# pse84 register map
Vendor: Infineon Technologies; Series: PSE84; File version: 1.0
CPU: CM33 r0p1, little endian, MPU, FPU, VTOR, 3 interrupt priority bits
Registers are 32-bit, read-write, reset 0x0 unless marked. A register's access mark holds for its fields unless they carry their own. Offsets are from the block's base; [hi:lo] are bit positions; lines under a group give offsets from that group; {n}, {i} and the like mark numbered series.

## LPPASS_MMIO — LPPASS top-level MMIO
Base 0x42EF0000
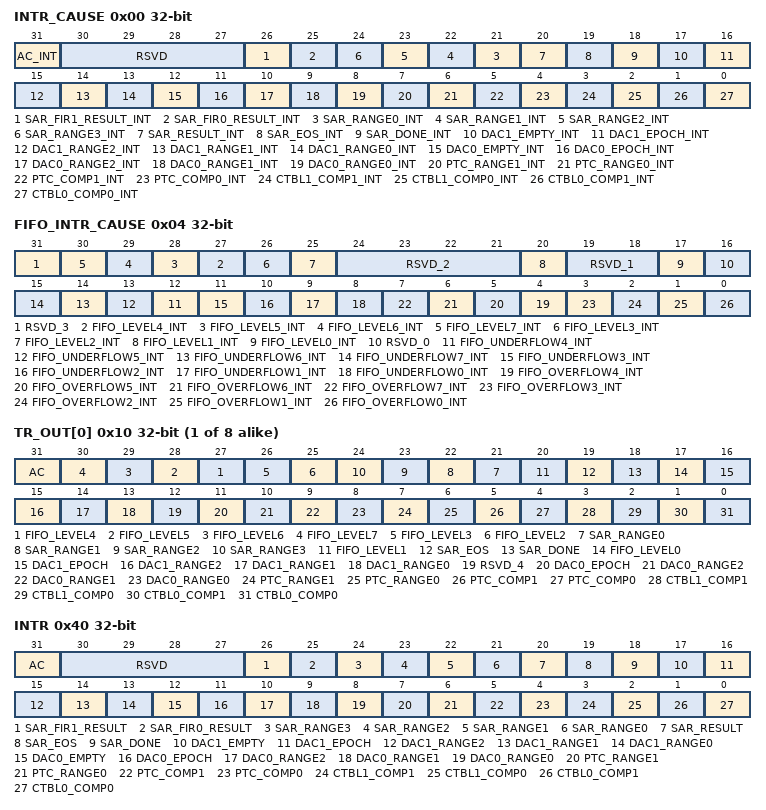
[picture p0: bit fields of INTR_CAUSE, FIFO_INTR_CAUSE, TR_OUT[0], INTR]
0x00 INTR_CAUSE ro — Interrupt cause register
  [31] AC_INT — Autonomus Controller Interrupt Pending This interrupt is set by the Autonomus Controller whenever executing a state with ACTRLR.TIMER_TABLE_STRUCT.TT_CFG1.INTR_SET=1.
  [30:27] RSVD
  [26] SAR_FIR1_RESULT_INT — FIR1 Result Interrupt Pending This interrupt is set by SAR FIR1 whenever it generates a new result. The corresponding bit in SAR_STA_CFG.FIR_RESULT_MASK must be set in order for the FIR to generate the interrupt source.
  [25] SAR_FIR0_RESULT_INT — FIR0 Result Interrupt Pending This interrupt is set by SAR FIR0 whenever it generates a new result. The corresponding bit in SAR_STA_CFG.FIR_RESULT_MASK must be set in order for the FIR to generate the interrupt source.
  [n+21] SAR_RANGE{n}_INT (n=0..3) — SAR Range {n} detection Interrupt Pending This interrupt is set by the SAR if the RANGE{n} condition is met for a given channel with range {n} status enabled (i.e. SAR_STA_CFG.GPIO(MUX)_CHAN_CFG.STATUS_SEL=STATUS_STRUCT_{n}). Firmware must read SAR_STA_CFG.RANGE_STATUS to determine which channel generated the interrupt.
  [20] SAR_RESULT_INT — SAR Result Interrupt Pending This interrupt is set by the SAR when a channel writes data into its associated result register. Firmware must read SAR_STA_CFG.CHAN_RESULT_UPDATED to determine which channel generated the interrupt. The corresponding bit in SAR_STA_CFG.CHAN_RESULT_MASK must be set in order for the SAR to generate the interrupt source.
  [19] SAR_EOS_INT — SAR Sequencer EOS Interrupt Pending This interrupt is set by the SAR when finishing the state in the SAR sequencer table (HS or LP) where SAR.SEQ_HS(LP)_DATA.NEXT_STATE is set to GO_TO_ENTRY_ADDRESS or STOP. This interrupt does NOT indicate that the SAR data has been written to the FIFO (the FIFO level interrupts should be used instead).
  [18] SAR_DONE_INT — SAR Sequencer Done Interrupt Pending This interrupt is set by the SAR when finishing a state in the SAR sequencer table (HS or LP) where SAR.SEQ_HS(LP)_DATA.NEXT_STATE is set to STOP. The interrupt is not generated if the SAR is configured for CONTINUOUS operation (i.e. SAR.SEQ_HS(LP)_DATA.NEXT_STATE is set to GO_TO_ENTRY_ADDRESS). This interrupt does NOT indicate that the SAR data has been written to the FIFO (the FIFO level interrupts should be used instead).
  [17] DAC1_EMPTY_INT — DAC1 Empty Interrupt Pending It is set by DAC1 when it empties the contents of its FW_DAC_VAL register. This interrupt is only generated if DAC1 is configured for FW operation (ACTRLR.TIMER_TABLE_STRUCT.TT_CFG3.DAC1_CHANNEL=FW_CHANNEL.
  [16] DAC1_EPOCH_INT — DAC1 End of Waveform Interrupt Pending It is set by DAC1 when finishing a waveform. This condition is only used if the DAC0 channel (pointed to by the AC when triggered) is configured for LUT mode.
  [15] DAC1_RANGE2_INT — DAC1 Range 2 Interrupt Pending It is set by the DAC1 if the RANGE2 condition is met for a given channel with range 2 status enabled (i.e. DAC1_STA_CFG.CHAN_CFG.STATUS_SEL=STATUS_2). The interrupt is disabled when DAC1 is configured for FW mode.
  [14] DAC1_RANGE1_INT — DAC1 Range 1 Interrupt Pending It is set by the DAC1 if the RANGE1 condition is met for a given channel with range 1 status enabled (i.e. DAC1_STA_CFG.CHAN_CFG.STATUS_SEL=STATUS_1). The interrupt is disabled when DAC1 is configured for FW mode.
  [13] DAC1_RANGE0_INT — DAC1 Range 0 Interrupt Pending It is set by the DAC1 if the RANGE0 condition is met for a given channel with range 0 status enabled (i.e. DAC1_STA_CFG.CHAN_CFG.STATUS_SEL=STATUS_0). The interrupt is disabled when DAC1 is configured for FW mode.
  [12] DAC0_EMPTY_INT — DAC0 Empty Interrupt Pending It is set by DAC0 when it empties the contents of its FW_DAC_VAL register. This interrupt is only generated if DAC0 is configured for FW operation (ACTRLR.TIMER_TABLE_STRUCT.TT_CFG3.DAC0_CHANNEL=FW_CHANNEL.
  [11] DAC0_EPOCH_INT — DAC0 End of Waveform Interrupt Pending It is set by DAC0 when finishing a waveform. This condition is only used if the DAC0 channel (pointed to by the AC when triggered) is configured for LUT mode.
  [10] DAC0_RANGE2_INT — DAC0 Range 2 Interrupt Pending It is set by the DAC0 if the RANGE2 condition is met for a given channel with range 2 status enabled (i.e. DAC0_STA_CFG.CHAN_CFG.STATUS_SEL=STATUS_2). The interrupt is disabled when DAC0 is configured for FW mode.
  [9] DAC0_RANGE1_INT — DAC0 Range 1 Interrupt Pending It is set by the DAC0 if the RANGE1 condition is met for a given channel with range 1 status enabled (i.e. DAC0_STA_CFG.CHAN_CFG.STATUS_SEL=STATUS_1). The interrupt is disabled when DAC0 is configured for FW mode.
  [8] DAC0_RANGE0_INT — DAC0 Range 0 Interrupt Pending It is set by the DAC0 if the RANGE0 condition is met for a given channel with range 0 status enabled (i.e. DAC0_STA_CFG.CHAN_CFG.STATUS_SEL=STATUS_0). The interrupt is disabled when DAC0 is configured for FW mode.
  [7] PTC_RANGE1_INT — PTC Post Processor 1 Range Interrupt Pending It is set by the PTC Post Processor if the RANGE0 condition is met (i.e. PTC_PP_STRUCT1.*).
  [6] PTC_RANGE0_INT — PTC Post Processor 0 Range Interrupt Pending It is set by the PTC Post Processor if the RANGE0 condition is met (i.e. PTC_PP_STRUCT0.*).
  [5] PTC_COMP1_INT — PTC Comparator 1 Interrupt Pending It is set by the PTC Comparator 1 if the condition is met (i.e. PTC_STA_CFG.CFG.COMP1_OUT field).
  [4] PTC_COMP0_INT — PTC Comparator 0 Interrupt Pending It is set by the PTC Comparator 0 if the condition is met (i.e. PTC_STA_CFG.CFG.COMP0_OUT field).
  [3] CTBL1_COMP1_INT — CTBL1 Comparator 1 Interrupt Pending It is set by the CTBL1 Opamp1 Comparator if the condition is met (i.e. CTBL_STA_CFG.CFG.COMP1_OUT field).
  [2] CTBL1_COMP0_INT — CTBL1 Comparator 0 Interrupt Pending It is set by the CTBL1 Opamp0 Comparator if the condition is met (i.e. CTBL_STA_CFG.CFG.COMP0_OUT field).
  [1] CTBL0_COMP1_INT — CTBL0 Comparator 1 Interrupt Pending It is set by the CTBL0 Opamp1 Comparator if the condition is met (i.e. CTBL_STA_CFG.CFG.COMP1_OUT field).
  [0] CTBL0_COMP0_INT — CTBL0 Comparator 0 Interrupt Pending It is set by the CTBL0 Opamp0 Comparator if the condition is met (i.e. CTBL_STA_CFG.CFG.COMP0_OUT field).
0x04 FIFO_INTR_CAUSE ro — FIFO Interrupt cause register
  [31] RSVD_3
  [n+23] FIFO_LEVEL{n}_INT (n=4..7) — FIFO Level {n} Interrupt Pending This level sensitive interrupt is set by the FIFO whenever FIFO {n} meets the FIFO_STA_CFG.LEVEL{n}.LEVEL condition. This interrupt is only generated if the FIFO is configured for multiple FIFOs (i.e. FIFO_STA_CFG.CFG.SEL=3)
  [26] FIFO_LEVEL3_INT — FIFO Level 3 Interrupt Pending This level sensitive interrupt is set by the FIFO whenever FIFO 3 meets the FIFO_STA_CFG.LEVEL3.LEVEL condition. This interrupt is only generated if the FIFO is configured for multiple FIFOs (i.e. FIFO_STA_CFG.CFG.SEL=2, or 3)
  [25] FIFO_LEVEL2_INT — FIFO Level 2 Interrupt Pending This level sensitive interrupt is set by the FIFO whenever FIFO 2 meets the FIFO_STA_CFG.LEVEL2.LEVEL condition. This interrupt is only generated if the FIFO is configured for multiple FIFOs (i.e. FIFO_STA_CFG.CFG.SEL=2, or 3)
  [24:21] RSVD_2
  [20] FIFO_LEVEL1_INT — FIFO Level 1 Interrupt Pending This level sensitive interrupt is set by the FIFO whenever FIFO 1 meets the FIFO_STA_CFG.LEVEL1.LEVEL condition. This interrupt is only generated if the FIFO is configured for multiple FIFOs (i.e. FIFO_STA_CFG.CFG.SEL=1,2, or 3)
  [19:18] RSVD_1
  [17] FIFO_LEVEL0_INT — FIFO Level 0 Interrupt Pending This level sensitive interrupt is set by the FIFO whenever FIFO 0 meets the FIFO_STA_CFG.LEVEL0.LEVEL condition.
  [16] RSVD_0
  [n+8] FIFO_UNDERFLOW{n}_INT (n=4..7) — FIFO Underflow {n} Interrupt Pending This interrupt is set by the FIFO whenever FIFO {n} underflows (i.e. a read from FIFO {n} fails because FIFO {n} is empty). This interrupt is only generated if the FIFO is configured for multiple FIFOs (i.e. FIFO_STA_CFG.CFG.SEL=3)
  [11] FIFO_UNDERFLOW3_INT — FIFO Overflow 3 Interrupt Pending This interrupt is set by the FIFO whenever FIFO 3 underflows (i.e. a read from FIFO 3 fails because FIFO 3 is empty). This interrupt is only generated if the FIFO is configured for multiple FIFOs (i.e. FIFO_STA_CFG.CFG.SEL=2, or 3)
  [10] FIFO_UNDERFLOW2_INT — FIFO Overflow 2 Interrupt Pending This interrupt is set by the FIFO whenever FIFO 2 underflows (i.e. a read from FIFO 2 fails because FIFO 2 is empty). This interrupt is only generated if the FIFO is configured for multiple FIFOs (i.e. FIFO_STA_CFG.CFG.SEL=2, or 3)
  [9] FIFO_UNDERFLOW1_INT — FIFO Overflow 1 Interrupt Pending This interrupt is set by the FIFO whenever FIFO 1 underflows (i.e. a read from FIFO 1 fails because FIFO 1 is empty). This interrupt is only generated if the FIFO is configured for multiple FIFOs (i.e. FIFO_STA_CFG.CFG.SEL=1,2, or 3)
  [8] FIFO_UNDERFLOW0_INT — FIFO Underflow 0 Interrupt Pending This interrupt is set by the FIFO whenever FIFO 0 underflows (i.e. a read from FIFO 0 fails because FIFO 0 is empty.
  [n] FIFO_OVERFLOW{n}_INT (n=4..7) — FIFO Overflow {n} Interrupt Pending This interrupt is set by the FIFO whenever FIFO {n} overflows (i.e. a write to FIFO {n} fails because FIFO {n} is full). This interrupt is only generated if the FIFO is configured for multiple FIFOs (i.e. FIFO_STA_CFG.CFG.SEL=3)
  [3] FIFO_OVERFLOW3_INT — FIFO Overflow 3 Interrupt Pending This interrupt is set by the FIFO whenever FIFO 3 overflows (i.e. a write to FIFO 3 fails because FIFO 3 is full). This interrupt is only generated if the FIFO is configured for multiple FIFOs (i.e. FIFO_STA_CFG.CFG.SEL=2, or 3)
  [2] FIFO_OVERFLOW2_INT — FIFO Overflow 2 Interrupt Pending This interrupt is set by the FIFO whenever FIFO 2 overflows (i.e. a write to FIFO 2 fails because FIFO 2 is full). This interrupt is only generated if the FIFO is configured for multiple FIFOs (i.e. FIFO_STA_CFG.CFG.SEL=2, or 3)
  [1] FIFO_OVERFLOW1_INT — FIFO Overflow 1 Interrupt Pending This interrupt is set by the FIFO whenever FIFO 1 overflows (i.e. a write to FIFO 1 fails because FIFO 1 is full). This interrupt is only generated if the FIFO is configured for multiple FIFOs (i.e. FIFO_STA_CFG.CFG.SEL=1,2, or 3)
  [0] FIFO_OVERFLOW0_INT — FIFO Overflow 0 Interrupt Pending This interrupt is set by the FIFO whenever FIFO 0 overflows (i.e. a write to FIFO 0 fails because FIFO 0 is full).
{0x10+4i} TR_OUT[{i}] (i=0..7) — Trigger out select register
  [31] AC — Autonomus Controller Trigger This trigger is set by the Autonomus Controller whenever executing a state with ACTRLR.TIMER_TABLE_STRUCT.TT_CFG1.INTR_SET=1.
  [n+23] FIFO_LEVEL{n} (n=4..7) — FIFO Level {n} Trigger This level sensitive trigger is set by the FIFO whenever FIFO {n} meets the FIFO_STA_CFG.LEVEL{n}.LEVEL condition. This trigger is only generated if the FIFO is configured for multiple FIFOs (i.e. FIFO_STA_CFG.CFG.SEL=3)
  [26] FIFO_LEVEL3 — FIFO Level 3 Trigger This level sensitive trigger is set by the FIFO whenever FIFO 3 meets the FIFO_STA_CFG.LEVEL3.LEVEL condition. This trigger is only generated if the FIFO is configured for multiple FIFOs (i.e. FIFO_STA_CFG.CFG.SEL=2, or 3)
  [25] FIFO_LEVEL2 — FIFO Level 2 Trigger This level sensitive trigger is set by the FIFO whenever FIFO 2 meets the FIFO_STA_CFG.LEVEL2.LEVEL condition. This trigger is only generated if the FIFO is configured for multiple FIFOs (i.e. FIFO_STA_CFG.CFG.SEL=2, or 3)
  [n+21] SAR_RANGE{n} (n=0..3) — SAR Range {n} Trigger This trigger is set by the SAR if the RANGE{n} condition is met for a given channel with range {n} status enabled (i.e. SAR_STA_CFG.GPIO(MUX)_CHAN_CFG.STATUS_SEL=STATUS_STRUCT_{n}). Firmware must read SAR_STA_CFG.RANGE_STATUS to determine which channel generated the trigger.
  [20] FIFO_LEVEL1 — FIFO Level 1 Trigger This level sensitive trigger is generated by the FIFO whenever FIFO 1 meets the FIFO_STA_CFG.LEVEL1.LEVEL condition. This trigger is only generated if the FIFO is configured for multiple FIFOs (i.e. FIFO_STA_CFG.CFG.SEL=1,2, or 3)
  [19] SAR_EOS — SAR Sequencer EOS Trigger This itrigger is set by the SAR when finishing the state in the SAR sequencer table (HS or LP) where SAR.SEQ_HS(LP)_DATA.NEXT_STATE is set to GO_TO_ENTRY_ADDRESS or STOP. This trigger does NOT indicate that the SAR data has been written to the FIFO (the FIFO level triggers should be used instead).
  [18] SAR_DONE — SAR Sequencer Done Trigger This trigger is set by the SAR when finishing a state in the SAR sequencer table (HS or LP) where SAR.SEQ_HS(LP)_DATA.NEXT_STATE is set to STOP. The interrupt is not generated if the SAR is configured for CONTINUOUS operation (i.e. SAR.SEQ_HS(LP)_DATA.NEXT_STATE is set to GO_TO_ENTRY_ADDRESS). This trigger does NOT indicate that the SAR data has been written to the FIFO (the FIFO level triggers should be used instead).
  [17] FIFO_LEVEL0 — FIFO Level 0 Trigger This is a level sensitive trigger that is generated by the FIFO whenever FIFO 0 meets the FIFO_STA_CFG.LEVEL0.LEVEL condition.
  [16] DAC1_EPOCH — DAC1 End of Waveform Trigger It is generated by DAC1 when finishing a waveform. This condition is only used if the DAC1 channel (pointed to by the AC when triggered) is configured for LUT mode.
  [15] DAC1_RANGE2 — DAC1 Range 2 Trigger It is generated by the DAC1 if the RANGE2 condition is met for a given channel with range 2 status enabled (i.e. DAC1_STA_CFG.CHAN_CFG.STATUS_SEL=STATUS_2). The interrupt is disabled when DAC1 is configured for FW mode.
  [14] DAC1_RANGE1 — DAC1 Range 1 Trigger It is generated by the DAC1 if the RANGE1 condition is met for a given channel with range 1 status enabled (i.e. DAC1_STA_CFG.CHAN_CFG.STATUS_SEL=STATUS_1). The interrupt is disabled when DAC1 is configured for FW mode.
  [13] DAC1_RANGE0 — DAC1 Range 0 Trigger It is generated by the DAC1 if the RANGE0 condition is met for a given channel with range 0 status enabled (i.e. DAC1_STA_CFG.CHAN_CFG.STATUS_SEL=STATUS_0). The interrupt is disabled when DAC1 is configured for FW mode.
  [12] RSVD_4
  [11] DAC0_EPOCH — DAC0 End of Waveform Trigger It is generated by DAC0 when finishing a waveform. This condition is only used if the DAC0 channel (pointed to by the AC when triggered) is configured for LUT mode.
  [10] DAC0_RANGE2 — DAC0 Range 2 Trigger It is generated by the DAC0 if the RANGE2 condition is met for a given channel with range 2 status enabled (i.e. DAC0_STA_CFG.CHAN_CFG.STATUS_SEL=STATUS_2). The interrupt is disabled when DAC0 is configured for FW mode.
  [9] DAC0_RANGE1 — DAC0 Range 1 Trigger It is generated by the DAC0 if the RANGE1 condition is met for a given channel with range 1 status enabled (i.e. DAC0_STA_CFG.CHAN_CFG.STATUS_SEL=STATUS_1). The interrupt is disabled when DAC0 is configured for FW mode.
  [8] DAC0_RANGE0 — DAC0 Range 0 Trigger It is generated by the DAC0 if the RANGE0 condition is met for a given channel with range 0 status enabled (i.e. DAC0_STA_CFG.CHAN_CFG.STATUS_SEL=STATUS_0). The interrupt is disabled when DAC0 is configured for FW mode.
  [7] PTC_RANGE1 — PTC Post Processor 1 Range Trigger It is generated by the PTC Post Processor if the RANGE0 condition is met (i.e. PTC_PP_STRUCT1.*).
  [6] PTC_RANGE0 — PTC Post Processor 0 Range Trigger It is generated by the PTC Post Processor if the RANGE0 condition is met (i.e. PTC_PP_STRUCT0.*).
  [5] PTC_COMP1 — PTC Comparator 1 Interrupt Pending It is set by the PTC Comparator 1 if the condition is met (i.e. PTC_STA_CFG.CFG.COMP1_OUT field).
  [4] PTC_COMP0 — PTC Comparator 0 Trigger It is set by the PTC Comparator 0 if the condition is met (i.e. PTC_STA_CFG.CFG.COMP0_OUT field).
  [3] CTBL1_COMP1 — CTBL1 Comparator 1 Trigger It is generated by the CTBL1 Opamp1 Comparator if the condition is met (i.e. CTBL_STA_CFG.CFG.COMP1_OUT field).
  [2] CTBL1_COMP0 — CTBL1 Comparator 0 Trigger It is generated by the CTBL1 Opamp0 Comparator if the condition is met (i.e. CTBL_STA_CFG.CFG.COMP0_OUT field).
  [1] CTBL0_COMP1 — CTBL0 Comparator 1 Trigger It is generated by the CTBL0 Opamp1 Comparator if the condition is met (i.e. CTBL_STA_CFG.CFG.COMP1_OUT field).
  [0] CTBL0_COMP0 — CTBL0 Comparator 0 Trigger It is generated by the CTBL0 Opamp0 Comparator if the condition is met (i.e. CTBL_STA_CFG.CFG.COMP0_OUT field).
0x40 INTR — Interrupt request register
  [31] AC — Autonomus Controller Interrupt Request AC Interrupt: hardware sets this interrupt when the Autonomus Controller executes a state with ACTRLR.TIMER_TABLE_STRUCT.TT_CFG1.INTR_SET=1.
  [30:27] RSVD
  [26] SAR_FIR1_RESULT — FIR1 Result Interrupt Request SAR FIR1 Result Interrupt: hardware sets this interrupt when SAR FIR1 generates a new result. The corresponding bit in SAR_STA_CFG.FIR_RESULT_MASK must be set in order for the FIR to generate the interrupt source. Write a '1' to clear bit.
  [25] SAR_FIR0_RESULT — FIR0 Result Interrupt Request SAR FIR0 Result Interrupt: hardware sets this interrupt when SAR FIR0 generates a new result. The corresponding bit in SAR_STA_CFG.FIR_RESULT_MASK must be set in order for the FIR to generate the interrupt source. Write a '1' to clear bit.
  [24] SAR_RANGE3 — SAR Range 3 detection Interrupt Request SAR Range 3 Interrupt: hardware sets this interrupt when the SAR RANGE3 condition is met for a given channel with range 3 status enabled (i.e. SAR_STA_CFG.GPIO(MUX)_CHAN_CFG.STATUS_SEL=STATUS_STRUCT_3). Firmware must read SAR_STA_CFG.RANGE_STATUS to determine which channel generated the interrupt. Write a '1' to clear bit.
  [23] SAR_RANGE2 — SAR Range2 detection Interrupt Request SAR Range 2 Interrupt: hardware sets this interrupt when the SAR RANGE2 condition is met for a given channel with range 2 status enabled (i.e. SAR_STA_CFG.GPIO(MUX)_CHAN_CFG.STATUS_SEL=STATUS_STRUCT_2). Firmware must read SAR_STA_CFG.RANGE_STATUS to determine which channel generated the interrupt. Write a '1' to clear bit.
  [22] SAR_RANGE1 — SAR Range 1 detection Interrupt Request SAR Range 1 Interrupt: hardware sets this interrupt when the SAR RANGE1 condition is met for a given channel with range 1 status enabled (i.e. SAR_STA_CFG.GPIO(MUX)_CHAN_CFG.STATUS_SEL=STATUS_STRUCT_1). Firmware must read SAR_STA_CFG.RANGE_STATUS to determine which channel generated the interrupt. Write a '1' to clear bit.
  [21] SAR_RANGE0 — SAR Range 0 detection Interrupt Request SAR Range 0 Interrupt: hardware sets this interrupt when the SAR RANGE0 condition is met for a given channel with range 0 status enabled (i.e. SAR_STA_CFG.GPIO(MUX)_CHAN_CFG.STATUS_SEL=STATUS_STRUCT_0). Firmware must read SAR_STA_CFG.RANGE_STATUS to determine which channel generated the interrupt. Write a '1' to clear bit.
  [20] SAR_RESULT — SAR Result Interrupt Request SAR Result Interrupt: hardware sets this interrupt when the SAR channel writes data into its associated result register. Firmware must read SAR_STA_CFG.CHAN_RESULT_UPDATED to determine which channel generated the interrupt. The corresponding bit in SAR_STA_CFG.CHAN_RESULT_MASK must be set in order for the SAR to generate the interrupt source. Write a '1' to clear bit.
  [19] SAR_EOS — SAR Sequencer EOS Interrupt Request SAR Sequencer EOS Interrupt: hardware sets this interrupt when the SAR finishes the state in the SAR sequencer table (HS or LP) where SAR.SEQ_HS(LP)_DATA.NEXT_STATE is set to GO_TO_ENTRY_ADDRESS or STOP. This interrupt does NOT indicate that the SAR data has been written to the FIFO (the FIFO level interrupts should be used instead). Write a '1' to clear bit.
  [18] SAR_DONE — SAR Sequencer Done Interrupt Request SAR Done Interrupt: hardware sets this interrupt when the SAR finishes a state in the SAR sequencer table (HS or LP) where SAR.SEQ_HS(LP)_DATA.NEXT_STATE is set to STOP. The interrupt is not generated if the SAR is configured for CONTINUOUS operation (i.e. SAR.SEQ_HS(LP)_DATA.NEXT_STATE is set to GO_TO_ENTRY_ADDRESS). This interrupt does NOT indicate that the SAR data has been written to the FIFO (the FIFO level interrupts should be used instead). Write a '1' to clear bit.
  [17] DAC1_EMPTY — DAC1 Empty Interrupt Request DAC1 Empty Interrupt: hardware sets this interrupt when DAC1 empties the contents of its FW_DAC_VAL register. This interrupt is only generated if DAC1 is configured for FW operation (ACTRLR.TIMER_TABLE_STRUCT.TT_CFG3.DAC1_CHANNEL=FW_CHANNEL. Write a '1' to clear bit.
  [16] DAC1_EPOCH — DAC1 End of Waveform Interrupt Request DAC1 EPOCH Interrupt: hardware sets this interrupt when DAC1 finishes a waveform. This condition is only used if the DAC1 channel (pointed to by the AC when triggered) is configured for LUT mode. Write a '1' to clear bit.
  [15] DAC1_RANGE2 — DAC1 Range 2 Interrupt Request DAC1 RANGE2 Interrupt: hardware sets this interrupt if the DAC1 RANGE2 condition is met for a given channel with range 2 status enabled (i.e. DAC1_STA_CFG.CHAN_CFG.STATUS_SEL=STATUS_2). The interrupt is disabled when DAC1 is configured for FW mode. Write with '1' to clear bit.
  [14] DAC1_RANGE1 — DAC1 Range 1 Interrupt Request DAC1 RANGE1 Interrupt: hardware sets this interrupt if the DAC0 RANGE1 condition is met for a given channel with range 1 status enabled (i.e. DAC1_STA_CFG.CHAN_CFG.STATUS_SEL=STATUS_1). The interrupt is disabled when DAC1 is configured for FW mode. Write with '1' to clear bit.
  [13] DAC1_RANGE0 — DAC1 Range 0 Interrupt Request DAC1 RANGE0 Interrupt: hardware sets this interrupt if the DAC1 RANGE0 condition is met for a given channel with range 0 status enabled (i.e. DAC1_STA_CFG.CHAN_CFG.STATUS_SEL=STATUS_0). The interrupt is disabled when DAC1 is configured for FW mode. Write with '1' to clear bit.
  [12] DAC0_EMPTY — DAC0 Empty Interrupt Request DAC0 Empty Interrupt: hardware sets this interrupt when DAC0 empties the contents of its FW_DAC_VAL register. This interrupt is only generated if DAC0 is configured for FW operation (ACTRLR.TIMER_TABLE_STRUCT.TT_CFG3.DAC0_CHANNEL=FW_CHANNEL. Write a '1' to clear bit.
  [11] DAC0_EPOCH — DAC0 End of Waveform Interrupt Request DAC0 EPOCH Interrupt: hardware sets this interrupt when DAC0 finishes a waveform. This condition is only used if the DAC0 channel (pointed to by the AC when triggered) is configured for LUT mode. Write a '1' to clear bit.
  [10] DAC0_RANGE2 — DAC0 Range 2 Interrupt Request DAC0 RANGE2 Interrupt: hardware sets this interrupt if the DAC0 RANGE2 condition is met for a given channel with range 2 status enabled (i.e. DAC0_STA_CFG.CHAN_CFG.STATUS_SEL=STATUS_2). The interrupt is disabled when DAC0 is configured for FW mode. Write with '1' to clear bit.
  [9] DAC0_RANGE1 — DAC0 Range 1 Interrupt Request DAC0 RANGE1 Interrupt: hardware sets this interrupt if the DAC0 RANGE1 condition is met for a given channel with range 1 status enabled (i.e. DAC0_STA_CFG.CHAN_CFG.STATUS_SEL=STATUS_1). The interrupt is disabled when DAC0 is configured for FW mode. Write with '1' to clear bit.
  [8] DAC0_RANGE0 — DAC0 Range 0 Interrupt Request DAC0 RANGE0 Interrupt: hardware sets this interrupt if the DAC0 RANGE0 condition is met for a given channel with range 0 status enabled (i.e. DAC0_STA_CFG.CHAN_CFG.STATUS_SEL=STATUS_0). The interrupt is disabled when DAC0 is configured for FW mode. Write with '1' to clear bit.
  [7] PTC_RANGE1 — PTC Post Processor 1 Range Interrupt Request PTC RANGE1 Interrupt: hardware sets this interrupt if the PTC Post Processor RANGE1 condition is met (i.e. PTC_PP_STRUCT1.*). Write with '1' to clear bit.
  [6] PTC_RANGE0 — PTC Post Processor 0 Range Interrupt Request PTC RANGE0 Interrupt: hardware sets this interrupt if the PTC Post Processor RANGE0 condition is met (i.e. PTC_PP_STRUCT0.*). Write with '1' to clear bit.
  [5] PTC_COMP1 — PTC Comparator 1 Interrupt Request PTC COMP1 Interrupt: hardware sets this interrupt if the condition is met (i.e. PTC_STA_CFG.CFG.COMP1_OUT field). Write with '1' to clear bit.
  [4] PTC_COMP0 — PTC Comparator 0 Interrupt Request PTC COMP0 Interrupt: hardware sets this interrupt if the condition is met (i.e. PTC_STA_CFG.CFG.COMP0_OUT field). Write with '1' to clear bit.
  [3] CTBL1_COMP1 — CTBL1 Comparator 1 Interrupt Request CTBL1 COMP1 Interrupt: hardware sets this interrupt if the condition is met (i.e. CTBL_STA_CFG.CFG.COMP1_OUT field). Write with '1' to clear bit.
  [2] CTBL1_COMP0 — CTBL1 Comparator 0 Interrupt Request CTBL1 COMP0 Interrupt: hardware sets this interrupt if the condition is met (i.e. CTBL_STA_CFG.CFG.COMP0_OUT field). Write with '1' to clear bit.
  [1] CTBL0_COMP1 — CTBL0 Comparator 1 Interrupt Request CTBL0 COMP1 Interrupt: hardware sets this interrupt if the condition is met (i.e. CTBL_STA_CFG.CFG.COMP1_OUT field). Write with '1' to clear bit.
  [0] CTBL0_COMP0 — CTBL0 Comparator 0 Interrupt Request CTBL0 COMP0 Interrupt: hardware sets this interrupt if the condition is met (i.e. CTBL_STA_CFG.CFG.COMP0_OUT field). Write with '1' to clear bit.
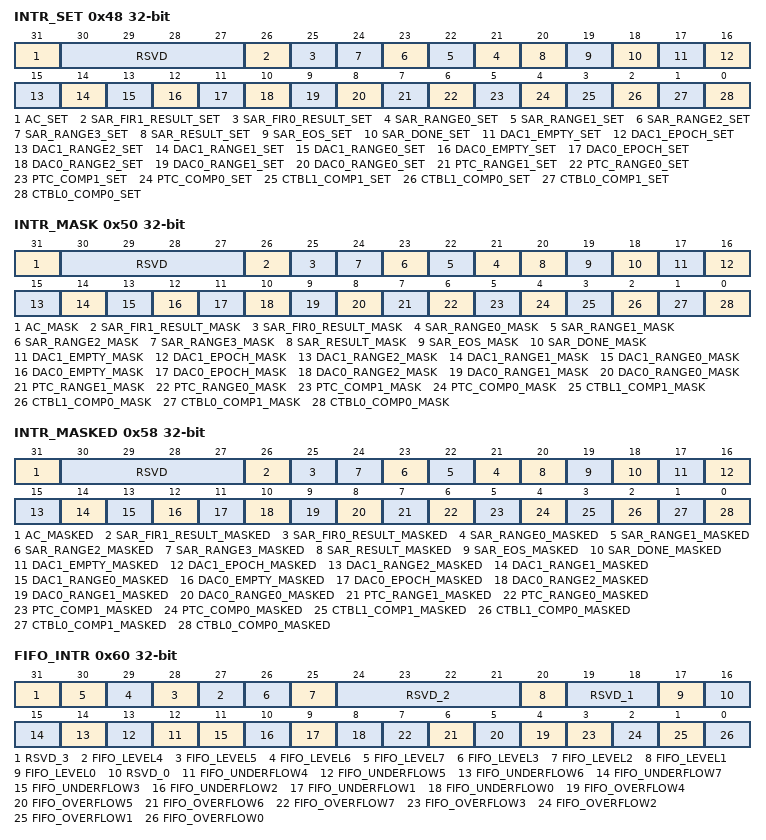
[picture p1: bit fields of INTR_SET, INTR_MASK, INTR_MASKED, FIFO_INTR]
0x48 INTR_SET — Interrupt request set register
  [31] AC_SET — Write with '1' to set corresponding bit in interrupt request register.
  [30:27] RSVD — Write with '1' to set corresponding bit in interrupt request register.
  [26] SAR_FIR1_RESULT_SET — Write with '1' to set corresponding bit in interrupt request register.
  [25] SAR_FIR0_RESULT_SET — Write with '1' to set corresponding bit in interrupt request register.
  [n+21] SAR_RANGE{n}_SET (n=0..3) — Write with '1' to set corresponding bit in interrupt request register.
  [20] SAR_RESULT_SET — Write with '1' to set corresponding bit in interrupt request register.
  [19] SAR_EOS_SET — Write with '1' to set corresponding bit in interrupt request register.
  [18] SAR_DONE_SET — Write with '1' to set corresponding bit in interrupt request register.
  [17] DAC1_EMPTY_SET — Write with '1' to set corresponding bit in interrupt request register.
  [16] DAC1_EPOCH_SET — Write with '1' to set corresponding bit in interrupt request register.
  [15] DAC1_RANGE2_SET — Write with '1' to set corresponding bit in interrupt request register.
  [14] DAC1_RANGE1_SET — Write with '1' to set corresponding bit in interrupt request register.
  [13] DAC1_RANGE0_SET — Write with '1' to set corresponding bit in interrupt request register.
  [12] DAC0_EMPTY_SET — Write with '1' to set corresponding bit in interrupt request register.
  [11] DAC0_EPOCH_SET — Write with '1' to set corresponding bit in interrupt request register.
  [10] DAC0_RANGE2_SET — Write with '1' to set corresponding bit in interrupt request register.
  [9] DAC0_RANGE1_SET — Write with '1' to set corresponding bit in interrupt request register.
  [8] DAC0_RANGE0_SET — Write with '1' to set corresponding bit in interrupt request register.
  [7] PTC_RANGE1_SET — Write with '1' to set corresponding bit in interrupt request register.
  [6] PTC_RANGE0_SET — Write with '1' to set corresponding bit in interrupt request register.
  [5] PTC_COMP1_SET — Write with '1' to set corresponding bit in interrupt request register.
  [4] PTC_COMP0_SET — Write with '1' to set corresponding bit in interrupt request register.
  [3] CTBL1_COMP1_SET — Write with '1' to set corresponding bit in interrupt request register.
  [2] CTBL1_COMP0_SET — Write with '1' to set corresponding bit in interrupt request register.
  [1] CTBL0_COMP1_SET — Write with '1' to set corresponding bit in interrupt request register.
  [0] CTBL0_COMP0_SET — Write with '1' to set corresponding bit in interrupt request register.
0x50 INTR_MASK — Interrupt request mask
  [31] AC_MASK — Mask bit for corresponding bit in interrupt request register.
  [30:27] RSVD — Mask bit for corresponding bit in interrupt request register.
  [26] SAR_FIR1_RESULT_MASK — Mask bit for corresponding bit in interrupt request register.
  [25] SAR_FIR0_RESULT_MASK — Mask bit for corresponding bit in interrupt request register.
  [n+21] SAR_RANGE{n}_MASK (n=0..3) — Mask bit for corresponding bit in interrupt request register.
  [20] SAR_RESULT_MASK — Mask bit for corresponding bit in interrupt request register.
  [19] SAR_EOS_MASK — Mask bit for corresponding bit in interrupt request register.
  [18] SAR_DONE_MASK — Mask bit for corresponding bit in interrupt request register.
  [17] DAC1_EMPTY_MASK — Mask bit for corresponding bit in interrupt request register.
  [16] DAC1_EPOCH_MASK — Mask bit for corresponding bit in interrupt request register.
  [15] DAC1_RANGE2_MASK — Mask bit for corresponding bit in interrupt request register.
  [14] DAC1_RANGE1_MASK — Mask bit for corresponding bit in interrupt request register.
  [13] DAC1_RANGE0_MASK — Mask bit for corresponding bit in interrupt request register.
  [12] DAC0_EMPTY_MASK — Mask bit for corresponding bit in interrupt request register.
  [11] DAC0_EPOCH_MASK — Mask bit for corresponding bit in interrupt request register.
  [10] DAC0_RANGE2_MASK — Mask bit for corresponding bit in interrupt request register.
  [9] DAC0_RANGE1_MASK — Mask bit for corresponding bit in interrupt request register.
  [8] DAC0_RANGE0_MASK — Mask bit for corresponding bit in interrupt request register.
  [7] PTC_RANGE1_MASK — Mask bit for corresponding bit in interrupt request register.
  [6] PTC_RANGE0_MASK — Mask bit for corresponding bit in interrupt request register.
  [5] PTC_COMP1_MASK — Mask bit for corresponding bit in interrupt request register.
  [4] PTC_COMP0_MASK — Mask bit for corresponding bit in interrupt request register.
  [3] CTBL1_COMP1_MASK — Mask bit for corresponding bit in interrupt request register.
  [2] CTBL1_COMP0_MASK — Mask bit for corresponding bit in interrupt request register.
  [1] CTBL0_COMP1_MASK — Mask bit for corresponding bit in interrupt request register.
  [0] CTBL0_COMP0_MASK — Mask bit for corresponding bit in interrupt request register.
0x58 INTR_MASKED ro — Interrupt request masked
  [31] AC_MASKED — Logical and of corresponding request and mask bits.
  [30:27] RSVD — Logical and of corresponding request and mask bits.
  [26] SAR_FIR1_RESULT_MASKED — Logical and of corresponding request and mask bits.
  [25] SAR_FIR0_RESULT_MASKED — Logical and of corresponding request and mask bits.
  [n+21] SAR_RANGE{n}_MASKED (n=0..3) — Logical and of corresponding request and mask bits.
  [20] SAR_RESULT_MASKED — Logical and of corresponding request and mask bits.
  [19] SAR_EOS_MASKED — Logical and of corresponding request and mask bits.
  [18] SAR_DONE_MASKED — Logical and of corresponding request and mask bits.
  [17] DAC1_EMPTY_MASKED — Logical and of corresponding request and mask bits.
  [16] DAC1_EPOCH_MASKED — Logical and of corresponding request and mask bits.
  [15] DAC1_RANGE2_MASKED — Logical and of corresponding request and mask bits.
  [14] DAC1_RANGE1_MASKED — Logical and of corresponding request and mask bits.
  [13] DAC1_RANGE0_MASKED — Logical and of corresponding request and mask bits.
  [12] DAC0_EMPTY_MASKED — Logical and of corresponding request and mask bits.
  [11] DAC0_EPOCH_MASKED — Logical and of corresponding request and mask bits.
  [10] DAC0_RANGE2_MASKED — Logical and of corresponding request and mask bits.
  [9] DAC0_RANGE1_MASKED — Logical and of corresponding request and mask bits.
  [8] DAC0_RANGE0_MASKED — Logical and of corresponding request and mask bits.
  [7] PTC_RANGE1_MASKED — Logical and of corresponding request and mask bits.
  [6] PTC_RANGE0_MASKED — Logical and of corresponding request and mask bits.
  [5] PTC_COMP1_MASKED — Logical and of corresponding request and mask bits.
  [4] PTC_COMP0_MASKED — Logical and of corresponding request and mask bits.
  [3] CTBL1_COMP1_MASKED — Logical and of corresponding request and mask bits.
  [2] CTBL1_COMP0_MASKED — Logical and of corresponding request and mask bits.
  [1] CTBL0_COMP1_MASKED — Logical and of corresponding request and mask bits.
  [0] CTBL0_COMP0_MASKED — Logical and of corresponding request and mask bits.
0x60 FIFO_INTR — FIFO Interrupt request register
  [31] RSVD_3
  [n+23] FIFO_LEVEL{n} ro (n=4..7) — FIFO Level {n} Interrupt Request FIFO Level {n} Interrupt: hardware sets this level sensitive interrupt whenever FIFO {n} meets the FIFO_STA_CFG.LEVEL{n}.LEVEL condition. This interrupt is only generated if the FIFO is configured for multiple FIFOs (i.e. FIFO_STA_CFG.CFG.SEL=3) This interrupt is only cleared when the contents of FIFO drop below the FIFO_STA_CFG.LEVEL{n}.LEVEL condition.
  [26] FIFO_LEVEL3 ro — FIFO Level 3 Interrupt Request FIFO Level 3 Interrupt: hardware sets this level sensitive interrupt whenever FIFO 3 meets the FIFO_STA_CFG.LEVEL3.LEVEL condition. This interrupt is only generated if the FIFO is configured for multiple FIFOs (i.e. FIFO_STA_CFG.CFG.SEL=2, or 3) This interrupt is only cleared when the contents of FIFO drop below the FIFO_STA_CFG.LEVEL3.LEVEL condition.
  [25] FIFO_LEVEL2 ro — FIFO Level 2 Interrupt Request FIFO Level 2 Interrupt: hardware sets this level sensitive interrupt whenever FIFO 2 meets the FIFO_STA_CFG.LEVEL2.LEVEL condition. This interrupt is only generated if the FIFO is configured for multiple FIFOs (i.e. FIFO_STA_CFG.CFG.SEL=2, or 3) This interrupt is only cleared when the contents of FIFO drop below the FIFO_STA_CFG.LEVEL2.LEVEL condition.
  [24:21] RSVD_2
  [20] FIFO_LEVEL1 ro — FIFO Level 1 Interrupt Request FIFO Level 1 Interrupt: hardware sets this level sensitive interrupt whenever FIFO 1 meets the FIFO_STA_CFG.LEVEL1.LEVEL condition. This interrupt is only generated if the FIFO is configured for multiple FIFOs (i.e. FIFO_STA_CFG.CFG.SEL=1,2, or 3) This interrupt is only cleared when the contents of FIFO drop below the FIFO_STA_CFG.LEVEL1.LEVEL condition.
  [19:18] RSVD_1
  [17] FIFO_LEVEL0 ro — FIFO Level 0 Interrupt Request FIFO Level 0 Interrupt: hardware sets this level sensitive interrupt whenever FIFO 0 meets the FIFO_STA_CFG.LEVEL0.LEVEL condition. This interrupt is only cleared when the contents of FIFO drop below the FIFO_STA_CFG.LEVEL0.LEVEL condition.
  [16] RSVD_0
  [n+8] FIFO_UNDERFLOW{n} (n=4..7) — FIFO Overflow {n} Interrupt Request FIFO Overflow {n} Interrupt: hardware sets this interrupt whenever FIFO {n} underflows (i.e. a read from FIFO {n} fails because FIFO {n} is empty). This interrupt is only generated if the FIFO is configured for multiple FIFOs (i.e. FIFO_STA_CFG.CFG.SEL=3) Write a '1' to clear bit.
  [11] FIFO_UNDERFLOW3 — FIFO Overflow 3 Interrupt Request FIFO Overflow 3 Interrupt: hardware sets this interrupt whenever FIFO 3 underflows (i.e. a read from FIFO 3 fails because FIFO 3 is empty). This interrupt is only generated if the FIFO is configured for multiple FIFOs (i.e. FIFO_STA_CFG.CFG.SEL=2, or 3) Write a '1' to clear bit.
  [10] FIFO_UNDERFLOW2 — FIFO Overflow 2 Interrupt Request FIFO Overflow 2 Interrupt: hardware sets this interrupt whenever FIFO 2 underflows (i.e. a read from FIFO 2 fails because FIFO 2 is empty). This interrupt is only generated if the FIFO is configured for multiple FIFOs (i.e. FIFO_STA_CFG.CFG.SEL=2, or 3) Write a '1' to clear bit.
  [9] FIFO_UNDERFLOW1 — FIFO Overflow 1 Interrupt Request FIFO Underflow 1 Interrupt: hardware sets this interrupt whenever FIFO 1 underflows (i.e. a read from FIFO 1 fails because FIFO 1 is empty). This interrupt is only generated if the FIFO is configured for multiple FIFOs (i.e. FIFO_STA_CFG.CFG.SEL=1,2, or 3) Write a '1' to clear bit.
  [8] FIFO_UNDERFLOW0 — FIFO Underflow 0 Interrupt Request FIFO Underflow 0 Interrupt: hardware sets this interrupt whenever FIFO 0 underflows (i.e. a read from FIFO 0 fails because FIFO 0 is empty. Write a '1' to clear bit.
  [n] FIFO_OVERFLOW{n} (n=4..7) — FIFO Overflow {n} Interrupt Request FIFO Overflow {n} Interrupt: hardware sets this interrupt whenever FIFO {n} overflows (i.e. a write to FIFO {n} fails because FIFO {n} is full). This interrupt is only generated if the FIFO is configured for multiple FIFOs (i.e. FIFO_STA_CFG.CFG.SEL=3) Write a '1' to clear bit.
  [3] FIFO_OVERFLOW3 — FIFO Overflow 3 Interrupt Request FIFO Overflow 3 Interrupt: hardware sets this interrupt whenever FIFO 3 overflows (i.e. a write to FIFO 3 fails because FIFO 3 is full). This interrupt is only generated if the FIFO is configured for multiple FIFOs (i.e. FIFO_STA_CFG.CFG.SEL=2, or 3) Write a '1' to clear bit.
  [2] FIFO_OVERFLOW2 — FIFO Overflow 2 Interrupt Request FIFO Overflow 2 Interrupt: hardware sets this interrupt whenever FIFO 2 overflows (i.e. a write to FIFO 2 fails because FIFO 2 is full). This interrupt is only generated if the FIFO is configured for multiple FIFOs (i.e. FIFO_STA_CFG.CFG.SEL=2, or 3) Write a '1' to clear bit.
  [1] FIFO_OVERFLOW1 — FIFO Overflow 1 Interrupt Request FIFO Overflow 1 Interrupt: hardware sets this interrupt whenever FIFO 1 overflows (i.e. a write to FIFO 1 fails because FIFO 1 is full). This interrupt is only generated if the FIFO is configured for multiple FIFOs (i.e. FIFO_STA_CFG.CFG.SEL=1,2, or 3) Write a '1' to clear bit.
  [0] FIFO_OVERFLOW0 — FIFO Overflow 0 Interrupt Request FIFO Overflow 0 Interrupt: hardware sets this interrupt whenever FIFO 0 overflows (i.e. a write to FIFO 0 fails because FIFO 0 is full). Write a '1' to clear bit.
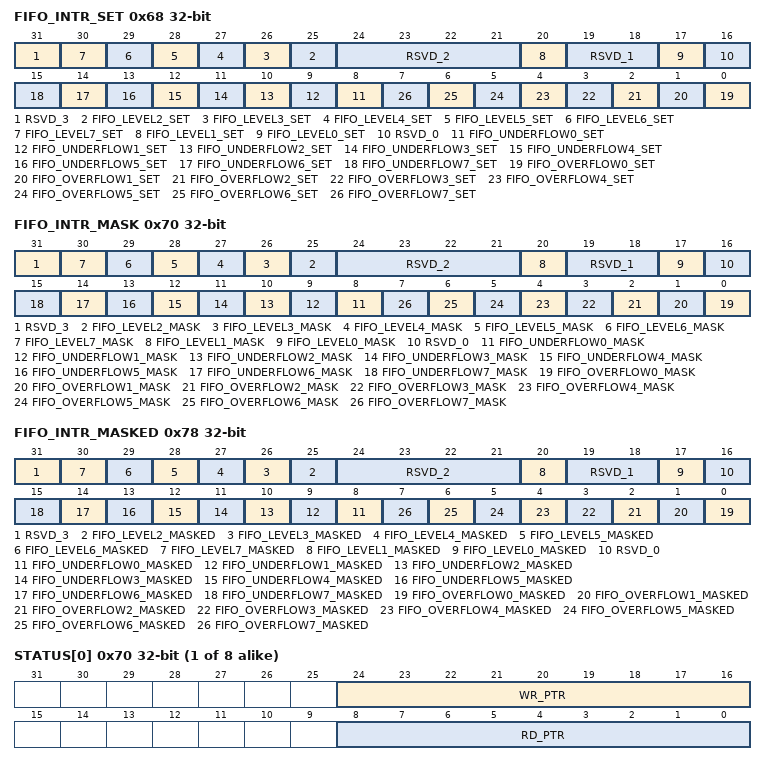
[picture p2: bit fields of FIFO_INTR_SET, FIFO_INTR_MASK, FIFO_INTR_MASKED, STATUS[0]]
0x68 FIFO_INTR_SET — FIFO Interrupt set request register
  [31] RSVD_3 — Write this field with '1' to set corresponding INTR field (a write of '0' has no effect).
  [n+23] FIFO_LEVEL{n}_SET (n=2..7) — Write this field with '1' to set corresponding INTR field (a write of '0' has no effect).
  [24:21] RSVD_2 — Write this field with '1' to set corresponding INTR field (a write of '0' has no effect).
  [20] FIFO_LEVEL1_SET — Write this field with '1' to set corresponding INTR field (a write of '0' has no effect).
  [19:18] RSVD_1 — Write this field with '1' to set corresponding INTR field (a write of '0' has no effect).
  [17] FIFO_LEVEL0_SET — Write this field with '1' to set corresponding INTR field (a write of '0' has no effect).
  [16] RSVD_0 — Write this field with '1' to set corresponding INTR field (a write of '0' has no effect).
  [n+8] FIFO_UNDERFLOW{n}_SET (n=0..7) — Write this field with '1' to set corresponding INTR field (a write of '0' has no effect).
  [n] FIFO_OVERFLOW{n}_SET (n=0..7) — Write this field with '1' to set corresponding INTR field (a write of '0' has no effect).
0x70 FIFO_INTR_MASK — FIFO Interrupt mask register
  [31] RSVD_3 — Mask for corresponding field in INTR register.
  [n+23] FIFO_LEVEL{n}_MASK (n=2..7) — Mask for corresponding field in INTR register.
  [24:21] RSVD_2 — Mask for corresponding field in INTR register.
  [20] FIFO_LEVEL1_MASK — Mask for corresponding field in INTR register.
  [19:18] RSVD_1 — Mask for corresponding field in INTR register.
  [17] FIFO_LEVEL0_MASK — Mask for corresponding field in INTR register.
  [16] RSVD_0 — Mask for corresponding field in INTR register.
  [n+8] FIFO_UNDERFLOW{n}_MASK (n=0..7) — Mask for corresponding field in INTR register.
  [n] FIFO_OVERFLOW{n}_MASK (n=0..7) — Mask for corresponding field in INTR register.
0x78 FIFO_INTR_MASKED ro — FIFO Interrupt masked request register
  [31] RSVD_3 — Logical AND of corresponding INTR and INTR_MASK fields.
  [n+23] FIFO_LEVEL{n}_MASKED (n=2..7) — Logical AND of corresponding INTR and INTR_MASK fields.
  [24:21] RSVD_2 — Logical AND of corresponding INTR and INTR_MASK fields.
  [20] FIFO_LEVEL1_MASKED — Logical AND of corresponding INTR and INTR_MASK fields.
  [19:18] RSVD_1 — Logical AND of corresponding INTR and INTR_MASK fields.
  [17] FIFO_LEVEL0_MASKED — Logical AND of corresponding INTR and INTR_MASK fields.
  [16] RSVD_0 — Logical AND of corresponding INTR and INTR_MASK fields.
  [n+8] FIFO_UNDERFLOW{n}_MASKED (n=0..7) — Logical AND of corresponding INTR and INTR_MASK fields.
  [n] FIFO_OVERFLOW{n}_MASKED (n=0..7) — Logical AND of corresponding INTR and INTR_MASK fields.
0x400 STA group — FIFO Static configuration
  0x00 CFG — FIFO configuration register.
    [1:0] SEL — FIFO Configuration Selection 0: FIFO configured for one 512 Entry FIFO (FIFO 0) 1: FIFO configured for two 256 Entry FIFOs: (FIFO 0-1) 2: FIFO configured for four 128 Entry FIFOs: (FIFO 0-3) 3: FIFO configured for eight 64 Entry FIFOs: (FIFO 0-7)
  0x04 MODE — FIFO mode register.
    [0] RD_LOCKOUT_EN — FIFO Read Lockout enable. This bit must be set before the chip mode transitions from active to deepsleep. This bit must be cleared before the system reads the FIFO. After changing the state of this bit, FW must poll MODE_STATUS.READ_LOCKOUT to determine when Lockout change takes effect. 0: Read Lockout disabled, FIFO contents can be read. 1: Read Lockout enabled, FIFO contents cannot be read.
  0x08 MODE_STATUS ro — FIFO mode status register.
    [0] RD_LOCKOUT — FIFO Read Lockout status. 0: FIFO is not in Read Lockout mode. The system can read the contents of the FIFO. 1: FIFO is in Read Lockout mode. The chip can enter deepsleep mode.
  {0x10+4j} LEVEL[{j}] (j=0..7) — FIFO level register.
    [8:0] LEVEL — FIFO level set. A trigger (and optional interrupt) event occurs when USED.USED = LEVEL+1.
  {0x30+4j} RD_DATA[{j}] (j=0..7) ro reset not defined — FIFO 32-bit read data register
    [31:0] RESULT — SAR 32-bit result.
  {0x50+4j} USED[{j}] (j=0..7) ro — FIFO used register
    [9:0] USED — Number of used/occupied entries in the FIFO.
  {0x70+4j} STATUS[{j}] (j=0..7) ro — FIFO status register
    [24:16] WR_PTR — FIFO write pointer: FIFO location at which a new data is written by the hardware. Note: This functionality is intended for debugging purposes.
    [8:0] RD_PTR — FIFO read pointer: FIFO location from which a data is read. Note: This functionality is intended for debugging purposes.
